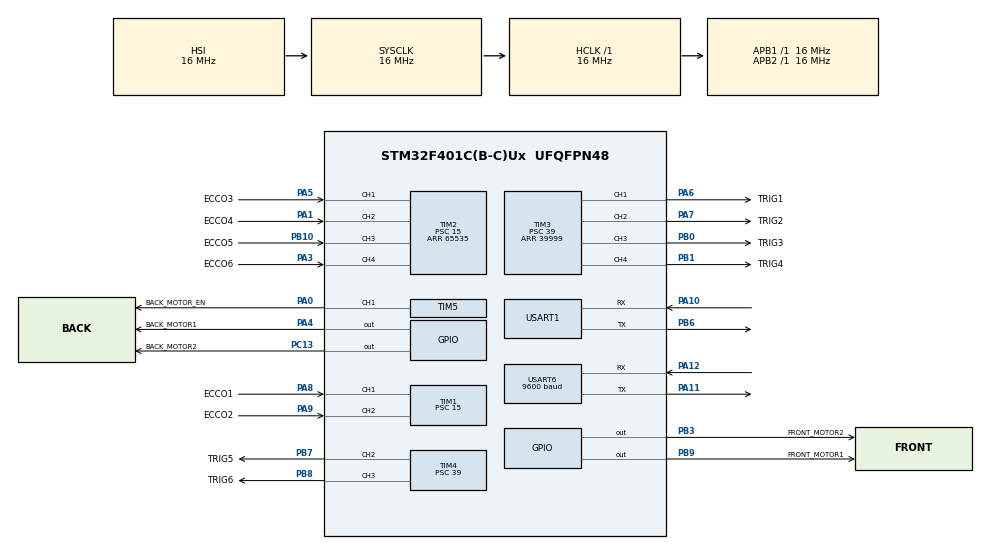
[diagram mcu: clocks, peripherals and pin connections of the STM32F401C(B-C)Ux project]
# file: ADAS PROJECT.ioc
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Mcu.Family=STM32F4
Mcu.Name=STM32F401C(B-C)Ux
Mcu.Package=UFQFPN48
NVIC.PriorityGroup=NVIC_PRIORITYGROUP_4
NVIC.TIM1_CC_IRQn=true\:0\:0\:false\:false\:true\:true\:true\:true
NVIC.TIM2_IRQn=true\:0\:0\:false\:false\:true\:true\:true\:true
NVIC.USART1_IRQn=true\:0\:0\:false\:false\:true\:true\:true\:true
NVIC.USART6_IRQn=true\:0\:0\:false\:false\:true\:true\:true\:true
PA0-WKUP.GPIO_Label=BACK_MOTOR_EN
PA0-WKUP.Signal=S_TIM5_CH1
PA1.GPIO_Label=ECCO4
PA1.Signal=S_TIM2_CH2
PA10.Mode=Asynchronous
PA10.Signal=USART1_RX
PA11.Mode=Asynchronous
PA11.Signal=USART6_TX
PA12.Mode=Asynchronous
PA12.Signal=USART6_RX
PA3.GPIO_Label=ECCO6
PA3.Signal=S_TIM2_CH4
PA4.GPIO_Label=BACK_MOTOR1
PA4.Signal=GPIO_Output
PA5.GPIO_Label=ECCO3
PA5.Signal=S_TIM2_CH1_ETR
PA6.GPIO_Label=TRIG1
PA6.Signal=S_TIM3_CH1
PA7.GPIO_Label=TRIG2
PA7.Signal=S_TIM3_CH2
PA8.GPIO_Label=ECCO1
PA8.Signal=S_TIM1_CH1
PA9.GPIO_Label=ECCO2
PA9.Signal=S_TIM1_CH2
PB0.GPIO_Label=TRIG3
PB0.Signal=S_TIM3_CH3
PB1.GPIO_Label=TRIG4
PB1.Signal=S_TIM3_CH4
PB10.GPIO_Label=ECCO5
PB10.Signal=S_TIM2_CH3
PB3.GPIO_Label=FRONT_MOTOR2
PB3.Signal=GPIO_Output
PB6.Mode=Asynchronous
PB6.Signal=USART1_TX
PB7.GPIO_Label=TRIG5
PB7.Signal=S_TIM4_CH2
PB8.GPIO_Label=TRIG6
PB8.Signal=S_TIM4_CH3
PB9.GPIO_Label=FRONT_MOTOR1
PB9.Signal=GPIO_Output
PC13-ANTI_TAMP.GPIO_Label=BACK_MOTOR2
PC13-ANTI_TAMP.Signal=GPIO_Output
ProjectManager.HeapSize=0x200
ProjectManager.StackSize=0x400
ProjectManager.TargetToolchain=STM32CubeIDE
RCC.AHBFreq_Value=16000000
RCC.APB1Freq_Value=16000000
RCC.APB2Freq_Value=16000000
RCC.CortexFreq_Value=16000000
RCC.HSE_VALUE=25000000
RCC.HSI_VALUE=16000000
RCC.LSE_VALUE=32768
RCC.SYSCLKFreq_VALUE=16000000
RCC.VCOOutputFreq_Value=192000000
SH.S_TIM1_CH1.0=TIM1_CH1,Input_Capture1_from_TI1
SH.S_TIM1_CH2.0=TIM1_CH2,Input_Capture2_from_TI2
SH.S_TIM2_CH1_ETR.0=TIM2_CH1,Input_Capture1_from_TI1
SH.S_TIM2_CH2.0=TIM2_CH2,Input_Capture2_from_TI2
SH.S_TIM2_CH3.0=TIM2_CH3,Input_Capture3_from_TI3
SH.S_TIM2_CH4.0=TIM2_CH4,Input_Capture4_from_TI4
SH.S_TIM3_CH1.0=TIM3_CH1,PWM Generation1 CH1
SH.S_TIM3_CH2.0=TIM3_CH2,PWM Generation2 CH2
SH.S_TIM3_CH3.0=TIM3_CH3,PWM Generation3 CH3
SH.S_TIM3_CH4.0=TIM3_CH4,PWM Generation4 CH4
SH.S_TIM4_CH2.0=TIM4_CH2,PWM Generation2 CH2
SH.S_TIM4_CH3.0=TIM4_CH3,PWM Generation3 CH3
SH.S_TIM5_CH1.0=TIM5_CH1,PWM Generation1 CH1
TIM1.Channel-Input_Capture1_from_TI1=TIM_CHANNEL_1
TIM1.Channel-Input_Capture2_from_TI2=TIM_CHANNEL_2
TIM1.Period=65535
TIM1.Prescaler=15
TIM11.Prescaler=15999
TIM2.Channel-Input_Capture1_from_TI1=TIM_CHANNEL_1
TIM2.Channel-Input_Capture2_from_TI2=TIM_CHANNEL_2
TIM2.Channel-Input_Capture3_from_TI3=TIM_CHANNEL_3
TIM2.Channel-Input_Capture4_from_TI4=TIM_CHANNEL_4
TIM2.Period=65535
TIM2.Prescaler=15
TIM3.Channel-PWM\ Generation1\ CH1=TIM_CHANNEL_1
TIM3.Channel-PWM\ Generation2\ CH2=TIM_CHANNEL_2
TIM3.Channel-PWM\ Generation3\ CH3=TIM_CHANNEL_3
TIM3.Channel-PWM\ Generation4\ CH4=TIM_CHANNEL_4
TIM3.Period=39999
TIM3.Prescaler=39
TIM4.Channel-PWM\ Generation2\ CH2=TIM_CHANNEL_2
TIM4.Channel-PWM\ Generation3\ CH3=TIM_CHANNEL_3
TIM4.Period=39999
TIM4.Prescaler=39
TIM5.Channel-PWM\ Generation1\ CH1=TIM_CHANNEL_1
TIM5.OCPolarity_1=TIM_OCPOLARITY_LOW
TIM5.Period=4096
USART1.VirtualMode=VM_ASYNC
USART6.BaudRate=9600
USART6.VirtualMode=VM_ASYNC
VP_TIM11_VS_ClockSourceINT.Mode=Enable_Timer
VP_TIM1_VS_ClockSourceINT.Mode=Internal
VP_TIM2_VS_ClockSourceINT.Mode=Internal
VP_TIM3_VS_ClockSourceINT.Mode=Internal
VP_TIM4_VS_ClockSourceINT.Mode=Internal
VP_TIM5_VS_ClockSourceINT.Mode=Internal
board=custom

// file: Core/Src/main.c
/* USER CODE BEGIN Header */
/**
 ******************************************************************************
 * @file           : main.c
 * @brief          : Main program body
 ******************************************************************************
 * @attention
 *
 * Copyright (c) 2023 STMicroelectronics.
 * All rights reserved.
 *
 * This software is licensed under terms that can be found in the LICENSE file
 * in the root directory of this software component.
 * If no LICENSE file comes with this software, it is provided AS-IS.
 *
 ******************************************************************************
 */
/* USER CODE END Header */
#include "main.h"

/* USER CODE BEGIN Includes */
#include "LCD_Interface.h"
#include "ultra_sonic_interface.h"
#include "ISR_CallBack_interface.h"
#include "dc_motor.h"
#include "AutoParking_Car_interface.h"

/* USER CODE END Includes */

TIM_HandleTypeDef htim1;
TIM_HandleTypeDef htim2;
TIM_HandleTypeDef htim3;
TIM_HandleTypeDef htim4;
TIM_HandleTypeDef htim5;
TIM_HandleTypeDef htim11;

UART_HandleTypeDef huart1;
UART_HandleTypeDef huart6;

/* USER CODE BEGIN PV */

u8 global_u8RxData ;
u8 s = 'S';

/* USER CODE END PV */

void SystemClock_Config(void);
static void MX_GPIO_Init(void);
static void MX_TIM2_Init(void);
static void MX_TIM1_Init(void);
static void MX_TIM4_Init(void);
static void MX_USART1_UART_Init(void);
static void MX_USART6_UART_Init(void);
static void MX_TIM11_Init(void);
static void MX_TIM5_Init(void);
static void MX_TIM3_Init(void);

int main(void)
{

  /* MCU Configuration--------------------------------------------------------*/

  /* Reset of all peripherals, Initializes the Flash interface and the Systick. */
  HAL_Init();

  /* Configure the system clock */
  SystemClock_Config();

  /* Initialize all configured peripherals */
  MX_GPIO_Init();
  MX_TIM2_Init();
  MX_TIM1_Init();
  MX_TIM4_Init();
  MX_USART1_UART_Init();
  MX_USART6_UART_Init();
  MX_TIM11_Init();
  MX_TIM5_Init();
  MX_TIM3_Init();
  /* USER CODE BEGIN 2 */

  HAL_UART_Receive_IT(&huart6,&global_u8RxData,1); // Enabling interrupt receive
  HAL_UART_Receive_IT(&huart1,&global_u8RxData,1); // Enabling interrupt receive

//	LCD_Init();
  	motor_vidInit();

//	__HAL_TIM_SET_COMPARE(&htim3,TIM_CHANNEL_1,4);
//	HAL_TIM_PWM_Start(&htim3, TIM_CHANNEL_1);
	Ultrasonic_vidInit();

//	HAL_TIM_PWM_Start(&htim3, TIM_CHANNEL_2);
//	HAL_TIM_PWM_Start(&htim3, TIM_CHANNEL_3);
//	HAL_TIM_PWM_Start(&htim3, TIM_CHANNEL_4);
//	HAL_TIM_PWM_Start(&htim4, TIM_CHANNEL_2);
//	HAL_TIM_PWM_Start(&htim4, TIM_CHANNEL_3);

//	__HAL_TIM_ENABLE_IT(&htim3, TIM_IT_CC2); // Enable capture/compare interrupt for Channel 2

//	for( u16 i = 0 ; i < 50 ; i++ )
//	{
//		HAL_Delay(100);
////		HAL_GPIO_TogglePin(GPIOB, GPIO_PIN_12);
////		LCD_GoTo(0, 1);
////		LCD_WriteChar(Car_u8getDirection());
//
////				LCD_GoTo(0, 0);
////				LCD_WriteString("   ");
////
////				  LCD_GoTo(0, 0);
////				LCD_WriteNumber(Get_Ultra_soinc_read(FORWARD_SENSOR));
//
//
//
//				LCD_GoTo(0, 4);
//				LCD_WriteString("   ");
//				LCD_GoTo(0, 4);
//				LCD_WriteNumber(Get_Ultra_soinc_read(FORWARD_SENSOR));
//
//
//				LCD_GoTo(0, 8);
//				LCD_WriteString("   ");
//				LCD_GoTo(0, 8);
//				LCD_WriteNumber(Get_Ultra_soinc_read(FORWARD_RIGHT_SENSOR));
//
//
////				LCD_GoTo(1, 0);
////				LCD_WriteString("   ");
////				LCD_GoTo(1, 0);
////				LCD_WriteNumber(Get_Ultra_soinc_read(BACKWARD_SENSOR));
//
//
//
//				LCD_GoTo(1, 4);
//				LCD_WriteString("   ");
//				LCD_GoTo(1, 4);
//				LCD_WriteNumber(Get_Ultra_soinc_read(FORWARD_LEFT_SENSOR));
//
//
//	}

//	HAL_TIM_PWM_Stop(&htim3, TIM_CHANNEL_2);

//

  /* USER CODE END 2 */

  /* Infinite loop */
  /* USER CODE BEGIN WHILE */
	while (1)
	{
		Car_vidRun();

//		HAL_Delay(5000);
//		motor_vidMoveForward(LOW_SPEED);
//		HAL_Delay(5000);
//		motor_vidMoveForwardLeft(LOW_SPEED);
//		HAL_Delay(5000);
//		motor_vidMoveForwardRight(LOW_SPEED);
//		HAL_Delay(5000);
//		motor_vidMoveBackward(LOW_SPEED);
//		HAL_Delay(5000);
//		motor_vidMoveBackwardLeft(LOW_SPEED);
//		HAL_Delay(5000);
//		motor_vidMoveBackwardRight(LOW_SPEED);
//		HAL_Delay(5000);
//		motor_vidStop();
//		HAL_Delay(5000);
//		dc_motor_move_forward(STOP_SPEED);
//		HAL_Delay(5000);

//		Ultra_sonic_start_read(FORWARD_SENSOR);
//		Ultra_sonic_start_read(FORWARD_LEFT_SENSOR);
	//	Ultra_sonic_start_read(FORWARD_RIGHT_SENSOR);
//		Ultra_sonic_start_read(BACKWARD_SENSOR);
//		Ultra_sonic_start_read(BACKWARD_LEFT_SENSOR);
//		Ultra_sonic_start_read(BACKWARD_RIGHT_SENSOR);

//		HAL_Delay(100);
//
//
//
////		LCD_GoTo(0, 1);
////		LCD_WriteChar(Car_u8getDirection());
//
////		LCD_GoTo(0, 0);
////		LCD_WriteString("   ");
////
////		  LCD_GoTo(0, 0);
////		LCD_WriteNumber(Get_Ultra_soinc_read(FORWARD_SENSOR));
//
//
//
//		LCD_GoTo(0, 4);
//		LCD_WriteString("   ");
//		LCD_GoTo(0, 4);
//		LCD_WriteNumber(Get_Ultra_soinc_read(FORWARD_SENSOR));
//
//
//		LCD_GoTo(0, 8);
//		LCD_WriteString("   ");
//		LCD_GoTo(0, 8);
//		LCD_WriteNumber(Get_Ultra_soinc_read(FORWARD_RIGHT_SENSOR));
//
//
////		LCD_GoTo(1, 0);
////		LCD_WriteString("   ");
////		LCD_GoTo(1, 0);
////		LCD_WriteNumber(Get_Ultra_soinc_read(BACKWARD_SENSOR));
//
//
//
//		LCD_GoTo(1, 4);
//		LCD_WriteString("   ");
//		LCD_GoTo(1, 4);
//		LCD_WriteNumber(Get_Ultra_soinc_read(FORWARD_LEFT_SENSOR));
//
//
//
//
////		LCD_GoTo(1, 8);
////		LCD_WriteString("   ");
////		LCD_GoTo(1, 8);
////		LCD_WriteNumber(Get_Ultra_soinc_read(BACKWARD_RIGHT_SENSOR));
//
//
//
//
//

    /* USER CODE END WHILE */

	}
}

void SystemClock_Config(void)
{
  RCC_OscInitTypeDef RCC_OscInitStruct = {0};
  RCC_ClkInitTypeDef RCC_ClkInitStruct = {0};

  /** Configure the main internal regulator output voltage
  */
  __HAL_RCC_PWR_CLK_ENABLE();
  __HAL_PWR_VOLTAGESCALING_CONFIG(PWR_REGULATOR_VOLTAGE_SCALE2);

  /** Initializes the RCC Oscillators according to the specified parameters
  * in the RCC_OscInitTypeDef structure.
  */
  RCC_OscInitStruct.OscillatorType = RCC_OSCILLATORTYPE_HSI;
  RCC_OscInitStruct.HSIState = RCC_HSI_ON;
  RCC_OscInitStruct.HSICalibrationValue = RCC_HSICALIBRATION_DEFAULT;
  RCC_OscInitStruct.PLL.PLLState = RCC_PLL_NONE;
  if (HAL_RCC_OscConfig(&RCC_OscInitStruct) != HAL_OK)
  {
    Error_Handler();
  }

  /** Initializes the CPU, AHB and APB buses clocks
  */
  RCC_ClkInitStruct.ClockType = RCC_CLOCKTYPE_HCLK|RCC_CLOCKTYPE_SYSCLK
                              |RCC_CLOCKTYPE_PCLK1|RCC_CLOCKTYPE_PCLK2;
  RCC_ClkInitStruct.SYSCLKSource = RCC_SYSCLKSOURCE_HSI;
  RCC_ClkInitStruct.AHBCLKDivider = RCC_SYSCLK_DIV1;
  RCC_ClkInitStruct.APB1CLKDivider = RCC_HCLK_DIV1;
  RCC_ClkInitStruct.APB2CLKDivider = RCC_HCLK_DIV1;

  if (HAL_RCC_ClockConfig(&RCC_ClkInitStruct, FLASH_LATENCY_0) != HAL_OK)
  {
    Error_Handler();
  }
}

static void MX_TIM1_Init(void)
{

  TIM_ClockConfigTypeDef sClockSourceConfig = {0};
  TIM_MasterConfigTypeDef sMasterConfig = {0};
  TIM_IC_InitTypeDef sConfigIC = {0};

  htim1.Instance = TIM1;
  htim1.Init.Prescaler = 15;
  htim1.Init.CounterMode = TIM_COUNTERMODE_UP;
  htim1.Init.Period = 65535;
  htim1.Init.ClockDivision = TIM_CLOCKDIVISION_DIV1;
  htim1.Init.RepetitionCounter = 0;
  htim1.Init.AutoReloadPreload = TIM_AUTORELOAD_PRELOAD_DISABLE;
  if (HAL_TIM_Base_Init(&htim1) != HAL_OK)
  {
    Error_Handler();
  }
  sClockSourceConfig.ClockSource = TIM_CLOCKSOURCE_INTERNAL;
  if (HAL_TIM_ConfigClockSource(&htim1, &sClockSourceConfig) != HAL_OK)
  {
    Error_Handler();
  }
  if (HAL_TIM_IC_Init(&htim1) != HAL_OK)
  {
    Error_Handler();
  }
  sMasterConfig.MasterOutputTrigger = TIM_TRGO_RESET;
  sMasterConfig.MasterSlaveMode = TIM_MASTERSLAVEMODE_DISABLE;
  if (HAL_TIMEx_MasterConfigSynchronization(&htim1, &sMasterConfig) != HAL_OK)
  {
    Error_Handler();
  }
  sConfigIC.ICPolarity = TIM_INPUTCHANNELPOLARITY_RISING;
  sConfigIC.ICSelection = TIM_ICSELECTION_DIRECTTI;
  sConfigIC.ICPrescaler = TIM_ICPSC_DIV1;
  sConfigIC.ICFilter = 0;
  if (HAL_TIM_IC_ConfigChannel(&htim1, &sConfigIC, TIM_CHANNEL_1) != HAL_OK)
  {
    Error_Handler();
  }
  if (HAL_TIM_IC_ConfigChannel(&htim1, &sConfigIC, TIM_CHANNEL_2) != HAL_OK)
  {
    Error_Handler();
  }

}

static void MX_TIM2_Init(void)
{

  TIM_ClockConfigTypeDef sClockSourceConfig = {0};
  TIM_MasterConfigTypeDef sMasterConfig = {0};
  TIM_IC_InitTypeDef sConfigIC = {0};

  htim2.Instance = TIM2;
  htim2.Init.Prescaler = 15;
  htim2.Init.CounterMode = TIM_COUNTERMODE_UP;
  htim2.Init.Period = 65535;
  htim2.Init.ClockDivision = TIM_CLOCKDIVISION_DIV1;
  htim2.Init.AutoReloadPreload = TIM_AUTORELOAD_PRELOAD_DISABLE;
  if (HAL_TIM_Base_Init(&htim2) != HAL_OK)
  {
    Error_Handler();
  }
  sClockSourceConfig.ClockSource = TIM_CLOCKSOURCE_INTERNAL;
  if (HAL_TIM_ConfigClockSource(&htim2, &sClockSourceConfig) != HAL_OK)
  {
    Error_Handler();
  }
  if (HAL_TIM_IC_Init(&htim2) != HAL_OK)
  {
    Error_Handler();
  }
  sMasterConfig.MasterOutputTrigger = TIM_TRGO_RESET;
  sMasterConfig.MasterSlaveMode = TIM_MASTERSLAVEMODE_DISABLE;
  if (HAL_TIMEx_MasterConfigSynchronization(&htim2, &sMasterConfig) != HAL_OK)
  {
    Error_Handler();
  }
  sConfigIC.ICPolarity = TIM_INPUTCHANNELPOLARITY_RISING;
  sConfigIC.ICSelection = TIM_ICSELECTION_DIRECTTI;
  sConfigIC.ICPrescaler = TIM_ICPSC_DIV1;
  sConfigIC.ICFilter = 0;
  if (HAL_TIM_IC_ConfigChannel(&htim2, &sConfigIC, TIM_CHANNEL_1) != HAL_OK)
  {
    Error_Handler();
  }
  if (HAL_TIM_IC_ConfigChannel(&htim2, &sConfigIC, TIM_CHANNEL_2) != HAL_OK)
  {
    Error_Handler();
  }
  if (HAL_TIM_IC_ConfigChannel(&htim2, &sConfigIC, TIM_CHANNEL_3) != HAL_OK)
  {
    Error_Handler();
  }
  if (HAL_TIM_IC_ConfigChannel(&htim2, &sConfigIC, TIM_CHANNEL_4) != HAL_OK)
  {
    Error_Handler();
  }

}

static void MX_TIM3_Init(void)
{

  TIM_ClockConfigTypeDef sClockSourceConfig = {0};
  TIM_MasterConfigTypeDef sMasterConfig = {0};
  TIM_OC_InitTypeDef sConfigOC = {0};

  htim3.Instance = TIM3;
  htim3.Init.Prescaler = 39;
  htim3.Init.CounterMode = TIM_COUNTERMODE_UP;
  htim3.Init.Period = 39999;
  htim3.Init.ClockDivision = TIM_CLOCKDIVISION_DIV1;
  htim3.Init.AutoReloadPreload = TIM_AUTORELOAD_PRELOAD_DISABLE;
  if (HAL_TIM_Base_Init(&htim3) != HAL_OK)
  {
    Error_Handler();
  }
  sClockSourceConfig.ClockSource = TIM_CLOCKSOURCE_INTERNAL;
  if (HAL_TIM_ConfigClockSource(&htim3, &sClockSourceConfig) != HAL_OK)
  {
    Error_Handler();
  }
  if (HAL_TIM_PWM_Init(&htim3) != HAL_OK)
  {
    Error_Handler();
  }
  sMasterConfig.MasterOutputTrigger = TIM_TRGO_RESET;
  sMasterConfig.MasterSlaveMode = TIM_MASTERSLAVEMODE_DISABLE;
  if (HAL_TIMEx_MasterConfigSynchronization(&htim3, &sMasterConfig) != HAL_OK)
  {
    Error_Handler();
  }
  sConfigOC.OCMode = TIM_OCMODE_PWM1;
  sConfigOC.Pulse = 0;
  sConfigOC.OCPolarity = TIM_OCPOLARITY_HIGH;
  sConfigOC.OCFastMode = TIM_OCFAST_DISABLE;
  if (HAL_TIM_PWM_ConfigChannel(&htim3, &sConfigOC, TIM_CHANNEL_1) != HAL_OK)
  {
    Error_Handler();
  }
  if (HAL_TIM_PWM_ConfigChannel(&htim3, &sConfigOC, TIM_CHANNEL_2) != HAL_OK)
  {
    Error_Handler();
  }
  if (HAL_TIM_PWM_ConfigChannel(&htim3, &sConfigOC, TIM_CHANNEL_3) != HAL_OK)
  {
    Error_Handler();
  }
  if (HAL_TIM_PWM_ConfigChannel(&htim3, &sConfigOC, TIM_CHANNEL_4) != HAL_OK)
  {
    Error_Handler();
  }
  HAL_TIM_MspPostInit(&htim3);

}

static void MX_TIM4_Init(void)
{

  TIM_ClockConfigTypeDef sClockSourceConfig = {0};
  TIM_MasterConfigTypeDef sMasterConfig = {0};
  TIM_OC_InitTypeDef sConfigOC = {0};

  htim4.Instance = TIM4;
  htim4.Init.Prescaler = 39;
  htim4.Init.CounterMode = TIM_COUNTERMODE_UP;
  htim4.Init.Period = 39999;
  htim4.Init.ClockDivision = TIM_CLOCKDIVISION_DIV1;
  htim4.Init.AutoReloadPreload = TIM_AUTORELOAD_PRELOAD_DISABLE;
  if (HAL_TIM_Base_Init(&htim4) != HAL_OK)
  {
    Error_Handler();
  }
  sClockSourceConfig.ClockSource = TIM_CLOCKSOURCE_INTERNAL;
  if (HAL_TIM_ConfigClockSource(&htim4, &sClockSourceConfig) != HAL_OK)
  {
    Error_Handler();
  }
  if (HAL_TIM_PWM_Init(&htim4) != HAL_OK)
  {
    Error_Handler();
  }
  sMasterConfig.MasterOutputTrigger = TIM_TRGO_RESET;
  sMasterConfig.MasterSlaveMode = TIM_MASTERSLAVEMODE_DISABLE;
  if (HAL_TIMEx_MasterConfigSynchronization(&htim4, &sMasterConfig) != HAL_OK)
  {
    Error_Handler();
  }
  sConfigOC.OCMode = TIM_OCMODE_PWM1;
  sConfigOC.Pulse = 0;
  sConfigOC.OCPolarity = TIM_OCPOLARITY_HIGH;
  sConfigOC.OCFastMode = TIM_OCFAST_DISABLE;
  if (HAL_TIM_PWM_ConfigChannel(&htim4, &sConfigOC, TIM_CHANNEL_2) != HAL_OK)
  {
    Error_Handler();
  }
  if (HAL_TIM_PWM_ConfigChannel(&htim4, &sConfigOC, TIM_CHANNEL_3) != HAL_OK)
  {
    Error_Handler();
  }
  HAL_TIM_MspPostInit(&htim4);

}

static void MX_TIM5_Init(void)
{

  TIM_ClockConfigTypeDef sClockSourceConfig = {0};
  TIM_MasterConfigTypeDef sMasterConfig = {0};
  TIM_OC_InitTypeDef sConfigOC = {0};

  htim5.Instance = TIM5;
  htim5.Init.Prescaler = 0;
  htim5.Init.CounterMode = TIM_COUNTERMODE_UP;
  htim5.Init.Period = 4096;
  htim5.Init.ClockDivision = TIM_CLOCKDIVISION_DIV1;
  htim5.Init.AutoReloadPreload = TIM_AUTORELOAD_PRELOAD_DISABLE;
  if (HAL_TIM_Base_Init(&htim5) != HAL_OK)
  {
    Error_Handler();
  }
  sClockSourceConfig.ClockSource = TIM_CLOCKSOURCE_INTERNAL;
  if (HAL_TIM_ConfigClockSource(&htim5, &sClockSourceConfig) != HAL_OK)
  {
    Error_Handler();
  }
  if (HAL_TIM_PWM_Init(&htim5) != HAL_OK)
  {
    Error_Handler();
  }
  sMasterConfig.MasterOutputTrigger = TIM_TRGO_RESET;
  sMasterConfig.MasterSlaveMode = TIM_MASTERSLAVEMODE_DISABLE;
  if (HAL_TIMEx_MasterConfigSynchronization(&htim5, &sMasterConfig) != HAL_OK)
  {
    Error_Handler();
  }
  sConfigOC.OCMode = TIM_OCMODE_PWM1;
  sConfigOC.Pulse = 0;
  sConfigOC.OCPolarity = TIM_OCPOLARITY_LOW;
  sConfigOC.OCFastMode = TIM_OCFAST_DISABLE;
  if (HAL_TIM_PWM_ConfigChannel(&htim5, &sConfigOC, TIM_CHANNEL_1) != HAL_OK)
  {
    Error_Handler();
  }
  HAL_TIM_MspPostInit(&htim5);

}

static void MX_TIM11_Init(void)
{

  htim11.Instance = TIM11;
  htim11.Init.Prescaler = 15999;
  htim11.Init.CounterMode = TIM_COUNTERMODE_UP;
  htim11.Init.Period = 65535;
  htim11.Init.ClockDivision = TIM_CLOCKDIVISION_DIV1;
  htim11.Init.AutoReloadPreload = TIM_AUTORELOAD_PRELOAD_DISABLE;
  if (HAL_TIM_Base_Init(&htim11) != HAL_OK)
  {
    Error_Handler();
  }

}

static void MX_USART1_UART_Init(void)
{

  huart1.Instance = USART1;
  huart1.Init.BaudRate = 115200;
  huart1.Init.WordLength = UART_WORDLENGTH_8B;
  huart1.Init.StopBits = UART_STOPBITS_1;
  huart1.Init.Parity = UART_PARITY_NONE;
  huart1.Init.Mode = UART_MODE_TX_RX;
  huart1.Init.HwFlowCtl = UART_HWCONTROL_NONE;
  huart1.Init.OverSampling = UART_OVERSAMPLING_16;
  if (HAL_UART_Init(&huart1) != HAL_OK)
  {
    Error_Handler();
  }

}

static void MX_USART6_UART_Init(void)
{

  huart6.Instance = USART6;
  huart6.Init.BaudRate = 9600;
  huart6.Init.WordLength = UART_WORDLENGTH_8B;
  huart6.Init.StopBits = UART_STOPBITS_1;
  huart6.Init.Parity = UART_PARITY_NONE;
  huart6.Init.Mode = UART_MODE_TX_RX;
  huart6.Init.HwFlowCtl = UART_HWCONTROL_NONE;
  huart6.Init.OverSampling = UART_OVERSAMPLING_16;
  if (HAL_UART_Init(&huart6) != HAL_OK)
  {
    Error_Handler();
  }

}

static void MX_GPIO_Init(void)
{
  GPIO_InitTypeDef GPIO_InitStruct = {0};

  /* GPIO Ports Clock Enable */
  __HAL_RCC_GPIOC_CLK_ENABLE();
  __HAL_RCC_GPIOA_CLK_ENABLE();
  __HAL_RCC_GPIOB_CLK_ENABLE();

  /*Configure GPIO pin Output Level */
  HAL_GPIO_WritePin(BACK_MOTOR2_GPIO_Port, BACK_MOTOR2_Pin, GPIO_PIN_RESET);

  /*Configure GPIO pin Output Level */
  HAL_GPIO_WritePin(BACK_MOTOR1_GPIO_Port, BACK_MOTOR1_Pin, GPIO_PIN_RESET);

  /*Configure GPIO pin Output Level */
  HAL_GPIO_WritePin(GPIOB, FRONT_MOTOR2_Pin|FRONT_MOTOR1_Pin, GPIO_PIN_RESET);

  /*Configure GPIO pin : BACK_MOTOR2_Pin */
  GPIO_InitStruct.Pin = BACK_MOTOR2_Pin;
  GPIO_InitStruct.Mode = GPIO_MODE_OUTPUT_PP;
  GPIO_InitStruct.Pull = GPIO_NOPULL;
  GPIO_InitStruct.Speed = GPIO_SPEED_FREQ_LOW;
  HAL_GPIO_Init(BACK_MOTOR2_GPIO_Port, &GPIO_InitStruct);

  /*Configure GPIO pin : BACK_MOTOR1_Pin */
  GPIO_InitStruct.Pin = BACK_MOTOR1_Pin;
  GPIO_InitStruct.Mode = GPIO_MODE_OUTPUT_PP;
  GPIO_InitStruct.Pull = GPIO_NOPULL;
  GPIO_InitStruct.Speed = GPIO_SPEED_FREQ_LOW;
  HAL_GPIO_Init(BACK_MOTOR1_GPIO_Port, &GPIO_InitStruct);

  /*Configure GPIO pins : FRONT_MOTOR2_Pin FRONT_MOTOR1_Pin */
  GPIO_InitStruct.Pin = FRONT_MOTOR2_Pin|FRONT_MOTOR1_Pin;
  GPIO_InitStruct.Mode = GPIO_MODE_OUTPUT_PP;
  GPIO_InitStruct.Pull = GPIO_NOPULL;
  GPIO_InitStruct.Speed = GPIO_SPEED_FREQ_LOW;
  HAL_GPIO_Init(GPIOB, &GPIO_InitStruct);

}

/* USER CODE BEGIN 4 */

//void HAL_UART_RxCpltCallback(UART_HandleTypeDef *huart)
//{
//  if(huart->Instance==USART6)
//  {
////	  if(global_u8RxData=='W' || global_u8RxData=='U' || global_u8RxData=='w' || global_u8RxData=='u')
////	  {
////		  global_u8CarMode = global_u8RxData;
////	  }
////	  else if(global_u8RxData=='F' || global_u8RxData=='B' || global_u8RxData=='L' || global_u8RxData=='R' ||
////			  global_u8RxData=='G' || global_u8RxData=='I' || global_u8RxData=='H' || global_u8RxData=='J' ||
////			  global_u8RxData=='S')
////	  {
////		  global_u8CarDirection = global_u8RxData;
////	  }
////	  else
////	  {
////		  /*
////		   * Do Nothing
////		   */
////	  }
//
//
////		  LCD_GoTo(0, 1);
////		  LCD_WriteChar(global_u8RxData);
//
//	  s =global_u8RxData;
//
//    HAL_UART_Receive_IT(&huart6,&global_u8RxData,1); // Enabling interrupt receive again
//  }
//}

/* USER CODE END 4 */

void Error_Handler(void)
{
	__disable_irq();
	while (1)
	{
	}
}
